# wl_phy_rxt_secure register map
Vendor: Texas Instruments
Peripheral module from a debugger description file (folder CC35X1E).
Registers are 32-bit, access per field, no defined reset value unless marked. A register's access mark holds for its fields unless they carry their own. Offsets are as the file gives them; lines under a group give offsets from that group; [hi:lo] are bit positions; {n}, {i} and the like mark numbered series; 'fields as' and 'values as' point back to an identical list; <NAME> marks a mode.

## wl_phy_rxt_secure (part 1 of 2)
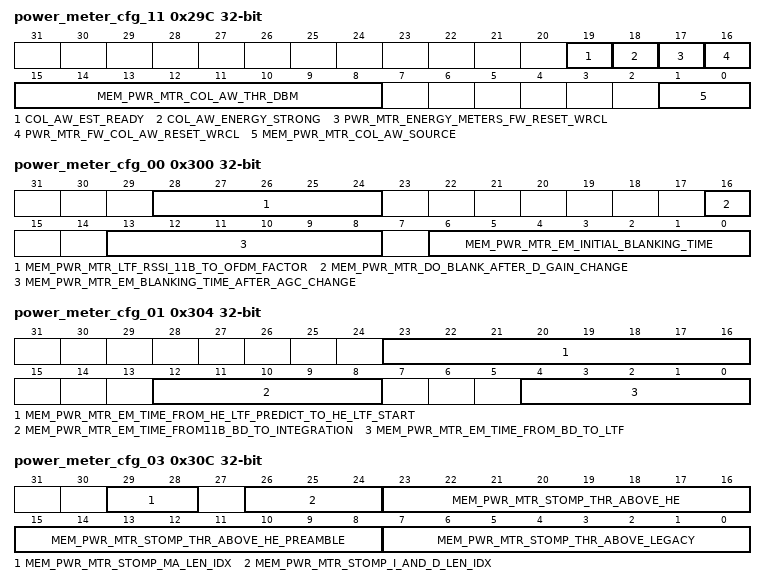
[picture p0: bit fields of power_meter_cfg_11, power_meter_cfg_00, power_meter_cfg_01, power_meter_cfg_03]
0x29C power_meter_cfg_11 — Collision Awareness Detector
  [19] COL_AW_EST_READY ro — Status, indicates that mem_col_aw_energy_strong reading is valid
  [18] COL_AW_ENERGY_STRONG ro — Status, high if module detected 'strong' energy
  [17] PWR_MTR_ENERGY_METERS_FW_RESET_WRCL wo — power estimation fw reset
  [16] PWR_MTR_FW_COL_AW_RESET_WRCL wo — Resets the collision awarenes detector so it can use next estimation
  [15:8] MEM_PWR_MTR_COL_AW_THR_DBM rw — Threshold value for comparisson
  [1:0] MEM_PWR_MTR_COL_AW_SOURCE rw — MUX control for path estimation
0x300 power_meter_cfg_00 — Rx PowerMeter configuration reg
  [28:24] MEM_PWR_MTR_LTF_RSSI_11B_TO_OFDM_FACTOR rw
  [16] MEM_PWR_MTR_DO_BLANK_AFTER_D_GAIN_CHANGE rw — 1 - Any DGain change will result in a 1-clock 'blanking' period, causing the estimation period to be re-synched with the new values. 0 - DGain changes will not cause a blanking period nor re-synching.
  [13:8] MEM_PWR_MTR_EM_BLANKING_TIME_AFTER_AGC_CHANGE rw — Duration MaskFSM stays in state Blanking (i.e. masked), following an AGC step. Not used for Digital-Gain change. [40MHz cycles]
  [6:0] MEM_PWR_MTR_EM_INITIAL_BLANKING_TIME rw — Duration MaskFSM stays in state Idle (i.e. masked), following turn on or RxEn. [40MHz cycles]
0x304 power_meter_cfg_01 — Rx PowerMeter configuration reg
  [23:16] MEM_PWR_MTR_EM_TIME_FROM_HE_LTF_PREDICT_TO_HE_LTF_START rw — Duration RssiLtfFSM stays in state WaitForHeLtfStart following entrance to HeStf. (in other words, time from RxControl FSM start of HeStf state, till HeLtf reaches energy meter)[40MHz cycles]
  [12:8] MEM_PWR_MTR_EM_TIME_FROM11B_BD_TO_INTEGRATION rw — Duration RssiLtfFSM stays in state WaitForLegLtfStart following an 11B 'BD' event. [40MHz cycles]
  [4:0] MEM_PWR_MTR_EM_TIME_FROM_BD_TO_LTF rw — Duration RssiLtfFSM stays in state WaitForLegLtfStart following a BD event from the TdAcq. This accounts for delay as well as propagation. [40MHz cycles]
0x308 power_meter_cfg_02 reset 0x8040 — Rx PowerMeter configuration reg
  [8:0] MEM_PWR_MTR_EM_NORM_FACTOR_DB rw — Norm factor. Should include dBFS to dBm, Trace Loss and gain variation. Formula for dBFS to dBm is 10log10(VFullScale^2/(R*10^-3)) = 10log10(VFullScale^2/(50*10^-3)) which is 13dB in case of FPGA and 7 in silicon. [dB] Default = 7dB * 2^ 3= 56 <6.3s>
0x30C power_meter_cfg_03 — Rx PowerMeter configuration reg
  [29:28] MEM_PWR_MTR_STOMP_MA_LEN_IDX rw — {0} Length is 1 (no MA) {1} Length is 2 {2} Length is 4 {3} Length is 8
  [26:24] MEM_PWR_MTR_STOMP_I_AND_D_LEN_IDX rw — {0} No I and D (input at 40MHz) {1} 100nSec I and D {2} 200nSec I and D {3} 400nSec I and D {4} Use configurable length I and D as input
  [23:16] MEM_PWR_MTR_STOMP_THR_ABOVE_HE rw — Stomp threshold used during HE parts. [dB above RSSI estimation on HE-LTF] default = 14dB*2^2 = 56 <6.2u>
  [15:8] MEM_PWR_MTR_STOMP_THR_ABOVE_HE_PREAMBLE rw — Stomp threshold used during HE-Preamble parts. [dB above RSSI estimation on L-LTF] default = 63.75dB*2^2 = 255 <6.2u>
  [7:0] MEM_PWR_MTR_STOMP_THR_ABOVE_LEGACY rw — Stomp threshold used during non-HE parts. [dB above RSSI estimation on L-LTF] default = 14dB*2^2 = 56 <6.2u>
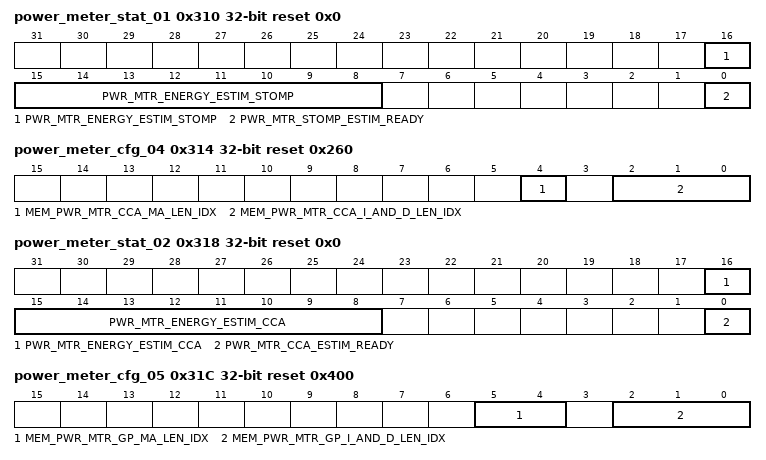
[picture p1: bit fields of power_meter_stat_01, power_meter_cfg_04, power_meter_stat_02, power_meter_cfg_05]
0x310 power_meter_stat_01 ro reset 0x0 — Rx PowerMeter Status reg
  [16:8] PWR_MTR_ENERGY_ESTIM_STOMP — Status Reg with energy estimation by Stomp path. Note that positive values in register indicate negative [dBm] (i.e. multiply with -1 and then shift, and then you get the dBm value) RO - <7.2u>
  [0] PWR_MTR_STOMP_ESTIM_READY — Status reg signifying Stomp energy estimation is valid and not during a mask RO
0x314 power_meter_cfg_04 reset 0x260 (reset mask 0xFFFFFFE0) — Rx PowerMeter configuration reg
  [4] MEM_PWR_MTR_CCA_MA_LEN_IDX rw — {0} Length is 1 (no MA) {1} Length is 2 Note that DGain changes might come at 800nSec intervals, so total CCA integration length should be shorter.
  [2:0] MEM_PWR_MTR_CCA_I_AND_D_LEN_IDX rw — {0} No I and D (input at 40MHz) {1} 100nSec I and D {2} 200nSec I and D {3} 400nSec I and D {4} Use configurable length I and D as input
0x318 power_meter_stat_02 ro reset 0x0 — Rx PowerMeter Status reg
  [16:8] PWR_MTR_ENERGY_ESTIM_CCA — Status Reg with energy estimation by CCA path. Note that positive values in register indicate negative [dBm] (i.e. multiply with -1 and then shift, and then you get the dBm value) RO - <7.2u>
  [0] PWR_MTR_CCA_ESTIM_READY — Status reg signifying CCA energy estimation is valid and not during a mask RO
0x31C power_meter_cfg_05 reset 0x400 (reset mask 0xFFFFFFC0) — Rx PowerMeter configuration reg
  [5:4] MEM_PWR_MTR_GP_MA_LEN_IDX rw — Note: Will only work when EnGpMa register is 1. {0} Length is 1 (no MA) {1} Length is 2 {2} Length is 4 {3} Length is 8
  [2:0] MEM_PWR_MTR_GP_I_AND_D_LEN_IDX rw — {0} No I and D (input at 40MHz) {1} 100nSec I and D {2} 200nSec I and D {3} 400nSec I and D {4} Use configurable length I and D as input
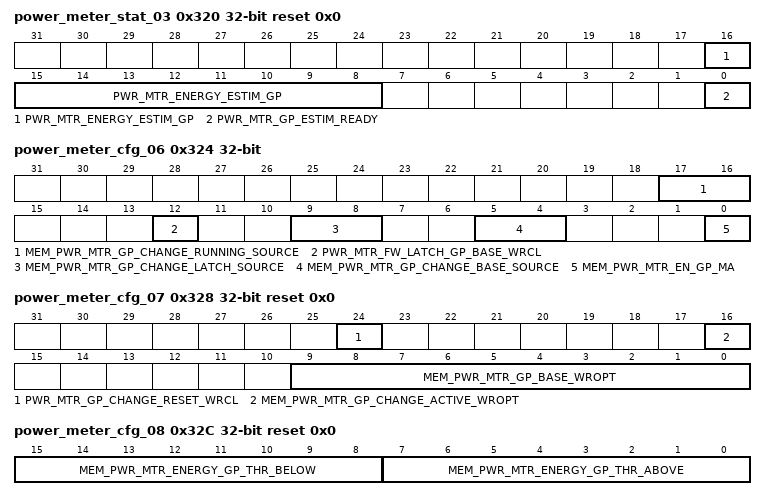
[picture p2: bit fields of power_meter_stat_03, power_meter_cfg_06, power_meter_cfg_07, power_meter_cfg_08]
0x320 power_meter_stat_03 ro reset 0x0 — Rx PowerMeter Status reg
  [16:8] PWR_MTR_ENERGY_ESTIM_GP — Status Reg with energy estimation by GP path. Note that positive values in register indicate negative [dBm] (i.e. multiply with -1 and then shift, and then you get the dBm value) RO - <7.2u>
  [0] PWR_MTR_GP_ESTIM_READY — Status reg signifying GP energy estimation is valid and not during a mask RO
0x324 power_meter_cfg_06 — Rx PowerMeter configuration reg
  [17:16] MEM_PWR_MTR_GP_CHANGE_RUNNING_SOURCE rw — Source of the GP 'Running' energy {0} - LTF RSSI {1} - Stomp MA {2} - CCA MA {3} - GP MA The running-energy chosen here is compared (with margins of EnergyGpThrAbove and EnergyGpThrBelow) with the 'baseline' energy chosen by GpChangeBaseSource (and latched by GpChangeLatchSource), to generate the GpEnergyHigh and GpEnergyLow IRQ's
  [12] PWR_MTR_FW_LATCH_GP_BASE_WRCL wo — (Self-Clear) When GpChangeLatchSource is set to {3}, a pulse in this register will latch the baseline energy and allow the GP energy change detector to start working. If the baseline energy is to be set by FW (and not latched from one of the energy estimations), GpChangeLatchSource should be set to {3}, baseline energy should be written into GpBase by FW, and a pulse here should NOT be initiated.
  [9:8] MEM_PWR_MTR_GP_CHANGE_LATCH_SOURCE rw
  [5:4] MEM_PWR_MTR_GP_CHANGE_BASE_SOURCE rw — Source of the GP 'baseline' energy. {0} - LTF RSSI {1} - Stomp MA {2} - CCA MA {3} - GP MA Note that the latching of the source into the 'baseline' depends on the GpChangeLatchSource register
  [0] MEM_PWR_MTR_EN_GP_MA rw — Saves power consumption when 0
0x328 power_meter_cfg_07 reset 0x0 — Rx PowerMeter configuration reg
  [24] PWR_MTR_GP_CHANGE_RESET_WRCL wo — Resets the GpChangeActive register to 0. This resetting should be done before the expected latching of the baseline. (Self-Clear)
  [16] MEM_PWR_MTR_GP_CHANGE_ACTIVE_WROPT rw — Marks that a latching of the GP-Baseline has taken place, and so the GP-energy-change detector readings are valid. This register is reset to 0 by the GpChangeReset register, and set to 1 automatically when the baseline latching occurs. Note that this register is also 'Write-Opt'. In case GP-Baseline is set by FW (and not latched automatically nor manually), FW may write this register to mark to any relevant entity that GP-Baseline is valid and that GP IRQs are up and running. Write-Opt
  [9:0] MEM_PWR_MTR_GP_BASE_WROPT rw — The GP baseline energy. ?????<8.5s>???? (Write-Opt) The source of this register may be an energy reading from the GpChangeBaseSource, or it may be written by FW. In case it is written by FW, the GpChangeLatchSource register should be set to {3}, and the FwLatchGpBase should be kept at 0. In case this register's source is not FW, the value in this reg is valid only after baseline is 'latched'. This is marked in the 'GpChangeActive' register.
0x32C power_meter_cfg_08 reset 0x0 — Rx PowerMeter configuration reg
  [15:8] MEM_PWR_MTR_ENERGY_GP_THR_BELOW rw — Any 'GP-Running' energy which is lower than GpBase by more than the value set in this register, will cause a 'GpEnergyLow' IRQ. Note that this is valid only after GpBase is valid (written in FW or latched as shown in GpChangeActive). [dB] Default 6gB --> 24 (<6.2>)
  [7:0] MEM_PWR_MTR_ENERGY_GP_THR_ABOVE rw — Any 'GP-Running' energy which is higher than GpBase by more than the value set in this register, will cause a 'GpEnergyHigh' IRQ. Note that this is valid only after GpBase is valid (written in FW or latched as shown in GpChangeActive). [dB] Default 6gB --> 24 (<6.2>)
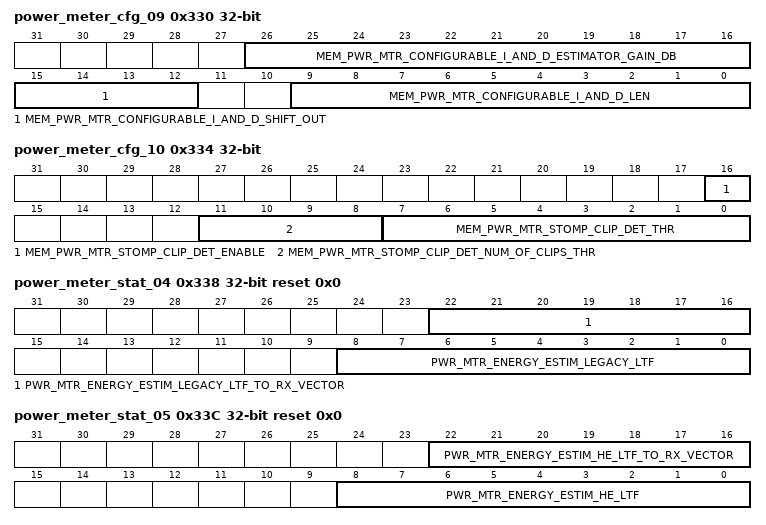
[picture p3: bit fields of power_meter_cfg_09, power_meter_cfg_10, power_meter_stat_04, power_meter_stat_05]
0x330 power_meter_cfg_09 — Rx PowerMeter configuration reg
  [26:16] MEM_PWR_MTR_CONFIGURABLE_I_AND_D_ESTIMATOR_GAIN_DB rw — The gain compensation of the configurable IandD, in [dB]. (based on its length, which is ConfigurableIandDLen, and on the number of output shifts, which is ConfigurableIandDShiftOut). The value from this register will be added to the estimated energy when using configurable I and D length. Default: 1.03125 (*2^32 )--> 33 (<6.5>)
  [15:12] MEM_PWR_MTR_CONFIGURABLE_I_AND_D_SHIFT_OUT rw — Number of right-shifts at configurable I and D module output. In general for integration length of 4 put 2, for integration length of 8 put 3, for integration length of 16 put 4, and so on. Supported range: (0,10) (<4.0>)
  [9:0] MEM_PWR_MTR_CONFIGURABLE_I_AND_D_LEN rw — Configurable I and D integration length. Used only when GpIandDLenIdx, CcaIandDLenIdx or StompIandDLenIdx are configured to {4} [40MHz clock cycles] <10.0u>
0x334 power_meter_cfg_10 — Rx PowerMeter configuration reg
  [16] MEM_PWR_MTR_STOMP_CLIP_DET_ENABLE rw, [11:8] MEM_PWR_MTR_STOMP_CLIP_DET_NUM_OF_CLIPS_THR rw, [7:0] MEM_PWR_MTR_STOMP_CLIP_DET_THR rw
0x338 power_meter_stat_04 ro reset 0x0 — Rx PowerMeter Status reg
  [22:16] PWR_MTR_ENERGY_ESTIM_LEGACY_LTF_TO_RX_VECTOR — Same as EnergyEstimLegacyLtf, but in format matching RxVector, i.e. 0=-110dBm, 127=17dBm RO - <7.0u>
  [8:0] PWR_MTR_ENERGY_ESTIM_LEGACY_LTF — Energy estimation of Legacy-LTF part. In 11B estimation is also performed. Locked automatically. Note that positive values in register indicate negative [dBm] (i.e. multiply with -1 and then shift, and then you get the dBm value) [-dBm]
0x33C power_meter_stat_05 ro reset 0x0 — Rx PowerMeter Status reg
  [22:16] PWR_MTR_ENERGY_ESTIM_HE_LTF_TO_RX_VECTOR — Same as EnergyEstimHeLtf, but in format matching RxVector, i.e. 0=-110dBm, 127=17dBm RO - <7.0u>
  [8:0] PWR_MTR_ENERGY_ESTIM_HE_LTF — Energy estimation of HE-LTF part. Locked automatically. Note that positive values in register indicate negative [dBm] (i.e. multiply with -1 and then shift, and then you get the dBm value) [-dBm] RO - <7.2u>
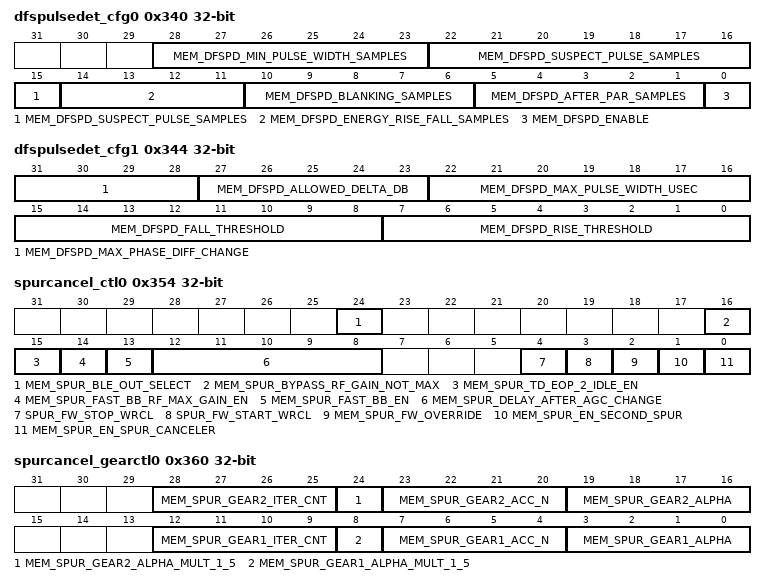
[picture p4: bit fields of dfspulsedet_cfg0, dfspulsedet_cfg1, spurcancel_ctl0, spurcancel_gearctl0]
0x340 dfspulsedet_cfg0 — DFSPulseDetector Configuration Register0
  [28:23] MEM_DFSPD_MIN_PULSE_WIDTH_SAMPLES rw — Format <6.0u>: Min pulse width in samples (40MHz)
  [22:15] MEM_DFSPD_SUSPECT_PULSE_SAMPLES rw — Format <8.0u>: Number of samples of low energy demanded after pulse s end
  [14:11] MEM_DFSPD_ENERGY_RISE_FALL_SAMPLES rw — Format <4.0u>: Number of samples in waiting states (see SM) after energy rise/fall
  [10:6] MEM_DFSPD_BLANKING_SAMPLES rw — Format <5.0u>: Number of samples waiting in BLANKING state
  [5:1] MEM_DFSPD_AFTER_PAR_SAMPLES rw — Format <5.0u>: Number of low samples needed to leave PAR state
  [0] MEM_DFSPD_ENABLE rw — DFS Pulse Detector Enable
0x344 dfspulsedet_cfg1 rw — DFSPulseDetector Configuration Register1
  [31:28] MEM_DFSPD_MAX_PHASE_DIFF_CHANGE — Format <0.4u>: Phase Diff threshold for chirp identification.
  [27:23] MEM_DFSPD_ALLOWED_DELTA_DB — Format <3.1u>: Allowed energy delta in dB. Used for stabilization identification.
  [22:16] MEM_DFSPD_MAX_PULSE_WIDTH_USEC — Format <7.0u>: Max pulse width in usec.
  [15:8] MEM_DFSPD_FALL_THRESHOLD — Format <6.0u>: Energy rise threshold in dB.
  [7:0] MEM_DFSPD_RISE_THRESHOLD — Format <6.0u>: Energy rise threshold in dB.
0x354 spurcancel_ctl0 — Spur Canceler Control Register 0
  [24] MEM_SPUR_BLE_OUT_SELECT rw
  [16] MEM_SPUR_BYPASS_RF_GAIN_NOT_MAX rw — If set, the spur canceler will be bypassed when RF gain is not at max value
  [15] MEM_SPUR_TD_EOP_2_IDLE_EN rw — If enabled, EOP packet pulse resets the SC correction into idle.
  [14] MEM_SPUR_FAST_BB_RF_MAX_GAIN_EN rw — If set, BB(VGA) change will cause scaling of the SC correction value (according to the VGA change) without reset of the SC module only when RF is in max gain (LNA+TA).
  [13] MEM_SPUR_FAST_BB_EN rw — If set, BB(VGA) change will cause scaling of the SC correction value (according to the VGA change) without reset of the SC module (spur is assumed constant during BB change).
  [12:8] MEM_SPUR_DELAY_AFTER_AGC_CHANGE rw — Format <5.0u>: Delay value after agc change (RfChange|BBChange) - Blanking. The delay is in 40 MHZ Samples
  [4] SPUR_FW_STOP_WRCL wo — Stop the SC correction - triggered from FW. Self Clear
  [3] SPUR_FW_START_WRCL wo — Start new SC correction - triggered from FW. Self Clear
  [2] MEM_SPUR_FW_OVERRIDE rw — If set, only the FW controls start/stop and not inner signals such as Abort/EOP/StartTd
  [1] MEM_SPUR_EN_SECOND_SPUR rw — Enabling the second spur removal
  [0] MEM_SPUR_EN_SPUR_CANCELER rw — Enable to the sequencer SM. If reset, the spur canceler is bypassed and the SM is disabled
0x358 spurcancel_freq1 reset 0x0 — Spur 1 Frequency Control Register
  [20:0] MEM_SPUR_FREQ1_DIV_FS rw — Format <0.21s>: The BB frequency of the first spur in units of DRX frequency (40MHz)
0x35C spurcancel_freq2 reset 0x0 — Spur 2 Frequency Control Register
  [20:0] MEM_SPUR_FREQ2_DIV_FS rw — Format <0.21s>: The BB frequency of the second spur in units of DRX frequency (40MHz)
0x360 spurcancel_gearctl0 — Spur Gear Control Register 0
  [28:25] MEM_SPUR_GEAR2_ITER_CNT rw — Format <4.0u>: Number of clocks to stay at Gear1. value is 2^(int)
  [24] MEM_SPUR_GEAR2_ALPHA_MULT_1_5 rw — 1.5 multiplier enable for Alfa of Gear 2
  [23:20] MEM_SPUR_GEAR2_ACC_N rw — Format <4.0u>: Accumulator duration (40Mhz cycles) for Gear2. Value is 2^(int). The value should be lower than Gear1IterCnt to produce at least a single correction in Gear2
  [19:16] MEM_SPUR_GEAR2_ALPHA rw — Format <4.0u>: Alfa value for Gear2. Value is (For example, value of 4 corresponds to 1/16).
  [12:9] MEM_SPUR_GEAR1_ITER_CNT rw — Format <4.0u>: Number of clocks to stay at Gear1. value is 2^(int)
  [8] MEM_SPUR_GEAR1_ALPHA_MULT_1_5 rw — 1.5 multiplier enable for Alfa of Gear 1
  [7:4] MEM_SPUR_GEAR1_ACC_N rw — Format <4.0u>: Accumulator duration (40Mhz cycles) for Gear1. Value is 2^(int). The value should be lower than Gear1IterCnt to produce at least a single correction in Gear1
  [3:0] MEM_SPUR_GEAR1_ALPHA rw — Format <4.0u>: Alfa value for Gear1. Value is (For example, value of 4 corresponds to 1/16).
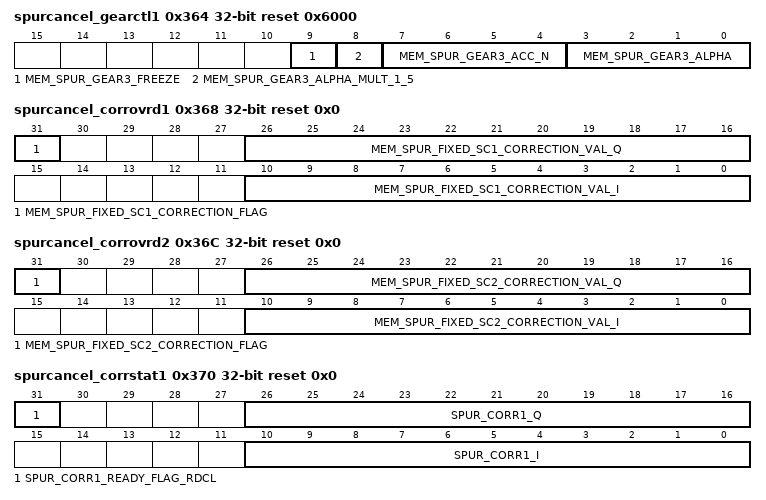
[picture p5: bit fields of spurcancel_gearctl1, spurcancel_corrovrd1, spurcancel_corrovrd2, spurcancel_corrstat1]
0x364 spurcancel_gearctl1 reset 0x6000 (reset mask 0xFFFFFC00) — Spur Gear Control Register 1
  [9] MEM_SPUR_GEAR3_FREEZE rw — Freeze adaptation for gear3
  [8] MEM_SPUR_GEAR3_ALPHA_MULT_1_5 rw — 1.5 multiplier enable for Alfa of Gear 3
  [7:4] MEM_SPUR_GEAR3_ACC_N rw — Format <4.0u>: Accumulator duration (40Mhz cycles) for Gear3. Value is 2^(int).
  [3:0] MEM_SPUR_GEAR3_ALPHA rw — Format <4.0u>: Alfa value for Gear3. Value is (For example, value of 4 corresponds to 1/16).
0x368 spurcancel_corrovrd1 reset 0x0 — Spur 1 Correction Override Register
  [31] MEM_SPUR_FIXED_SC1_CORRECTION_FLAG rw — If set, overwrite spur1 correction by FixedSc1CorrectionVal_XX
  [26:16] MEM_SPUR_FIXED_SC1_CORRECTION_VAL_Q rw — Format <0.11s>: Imaginary part of external forced spur1 correction
  [10:0] MEM_SPUR_FIXED_SC1_CORRECTION_VAL_I rw — Format <0.11s>: Real part of external forced spur1 correction
0x36C spurcancel_corrovrd2 reset 0x0 — Spur 2 Correction Override Register
  [31] MEM_SPUR_FIXED_SC2_CORRECTION_FLAG rw — If set, overwrite spur2 correction by FixedSc2CorrectionVal_XX
  [26:16] MEM_SPUR_FIXED_SC2_CORRECTION_VAL_Q rw — Format <0.11s>: Imaginary part of external forced spur2 correction
  [10:0] MEM_SPUR_FIXED_SC2_CORRECTION_VAL_I rw — Format <0.11s>: Real part of external forced spur2 correction
0x370 spurcancel_corrstat1 ro reset 0x0 — Spur 1 Correction Status Register
  [31] SPUR_CORR1_READY_FLAG_RDCL — Set to high every update of Corr value.
  [26:16] SPUR_CORR1_Q — Format <0.11s>: Spur correction value to be applied on the first DC cancellation sub-module. This value corresponds to the 1st Spur level.
  [10:0] SPUR_CORR1_I — Format <0.11s>: Spur correction value to be applied on the first DC cancellation sub-module. This value corresponds to the 1st Spur level.
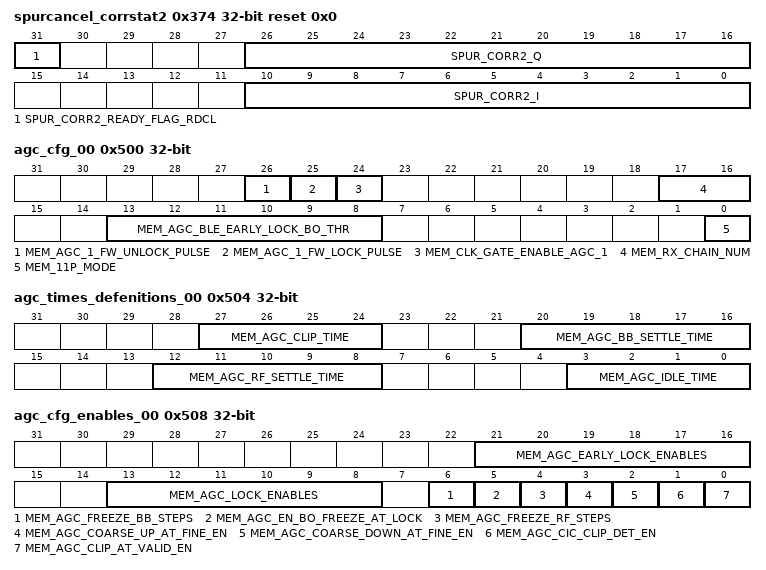
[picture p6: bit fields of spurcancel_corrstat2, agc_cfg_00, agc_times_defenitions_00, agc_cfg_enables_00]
0x374 spurcancel_corrstat2 ro reset 0x0 — Spur 2 Correction Status Register
  [31] SPUR_CORR2_READY_FLAG_RDCL — Set to high every update of Corr value.
  [26:16] SPUR_CORR2_Q — Format <0.11s>: Spur correction value to be applied on the first DC cancellation sub-module. This value corresponds to the 2nd Spur level.
  [10:0] SPUR_CORR2_I — Format <0.11s>: Spur correction value to be applied on the first DC cancellation sub-module. This value corresponds to the 2nd Spur level.
0x500 agc_cfg_00
  [26] MEM_AGC_1_FW_UNLOCK_PULSE rw, [25] MEM_AGC_1_FW_LOCK_PULSE rw, [24] MEM_CLK_GATE_ENABLE_AGC_1 rw, [17:16] MEM_RX_CHAIN_NUM rw, [13:8] MEM_AGC_BLE_EARLY_LOCK_BO_THR rw, [0] MEM_11P_MODE rw
0x504 agc_times_defenitions_00
  [27:24] MEM_AGC_CLIP_TIME rw — Settling time for clip event.
  [20:16] MEM_AGC_BB_SETTLE_TIME rw — Time for VGA will settle after gain step.Field value is number of samples
  [12:8] MEM_AGC_RF_SETTLE_TIME rw — Time for LNA/TA will settle after gain step. Field value is number of samples
  [3:0] MEM_AGC_IDLE_TIME rw
0x508 agc_cfg_enables_00
  [21:16] MEM_AGC_EARLY_LOCK_ENABLES rw — OneHotEarly LockPolicy: BD, BD_11b, PD, PD+delay, PD_11b, AGC 1st step+delay. 0-dont lock 1-lock at the first event
  [13:8] MEM_AGC_LOCK_ENABLES rw
  [6] MEM_AGC_FREEZE_BB_STEPS rw — When asserted BB steps are not allowed
  [5] MEM_AGC_EN_BO_FREEZE_AT_LOCK rw — BD, BD_11b, PD, PD+delay, PD_11b, AGC 1st step+delay.
  [4] MEM_AGC_FREEZE_RF_STEPS rw — When asserted RF steps are not allowed
  [3] MEM_AGC_COARSE_UP_AT_FINE_EN rw — When false, disabled the CompCoarseHigh at Fine state
  [2] MEM_AGC_COARSE_DOWN_AT_FINE_EN rw — When false, disabled the CompCoarseLow at Fine state
  [1] MEM_AGC_CIC_CLIP_DET_EN rw — Enable bit for clip detector
  [0] MEM_AGC_CLIP_AT_VALID_EN rw — Bit enable for consider clipping at power valid state
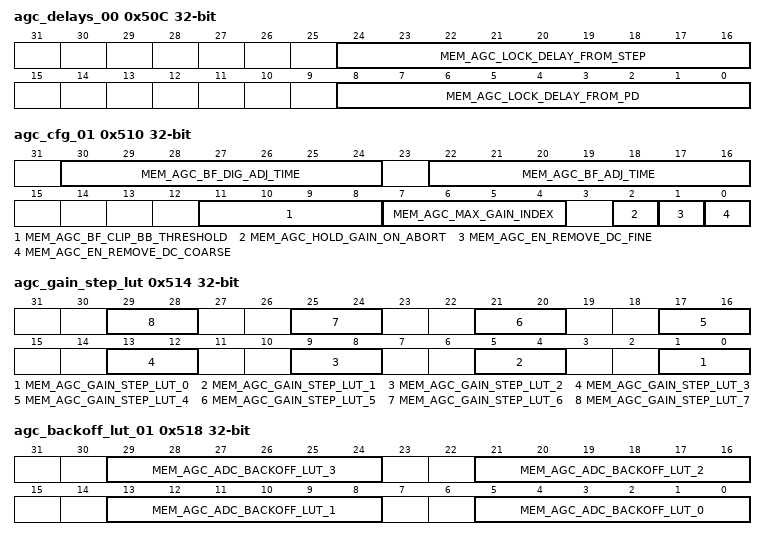
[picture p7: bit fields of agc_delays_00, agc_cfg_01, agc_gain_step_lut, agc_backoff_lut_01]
0x50C agc_delays_00
  [24:16] MEM_AGC_LOCK_DELAY_FROM_STEP rw — Delay from PD used for Mask lock policy policy (Used both for early Lock or Lock)
  [8:0] MEM_AGC_LOCK_DELAY_FROM_PD rw — Delay from AGC 1st step used for Mask lock policy (Used both for early Lock or Lock)
0x510 agc_cfg_01
  [30:24] MEM_AGC_BF_DIG_ADJ_TIME rw
  [22:16] MEM_AGC_BF_ADJ_TIME rw — Re adjustment time of the AGC in the HE-STF
  [11:8] MEM_AGC_BF_CLIP_BB_THRESHOLD rw
  [7:4] MEM_AGC_MAX_GAIN_INDEX rw — 1 lock at the first event
  [2] MEM_AGC_HOLD_GAIN_ON_ABORT rw — 0 dont lock
  [1] MEM_AGC_EN_REMOVE_DC_FINE rw — Bit Enable decide if remove DC from fine power estimation
  [0] MEM_AGC_EN_REMOVE_DC_COARSE rw — Bit Enable decide if remove DC from coarse power estimation
0x514 agc_gain_step_lut
  [4n+1:4n] MEM_AGC_GAIN_STEP_LUT_{n} rw (n=0..7) — Step size for each RF index (just for low)
0x518 agc_backoff_lut_01
  [8n+5:8n] MEM_AGC_ADC_BACKOFF_LUT_{n} rw (n=0..3) — Analog Backoff for each Rf index [dB] <5.1u>
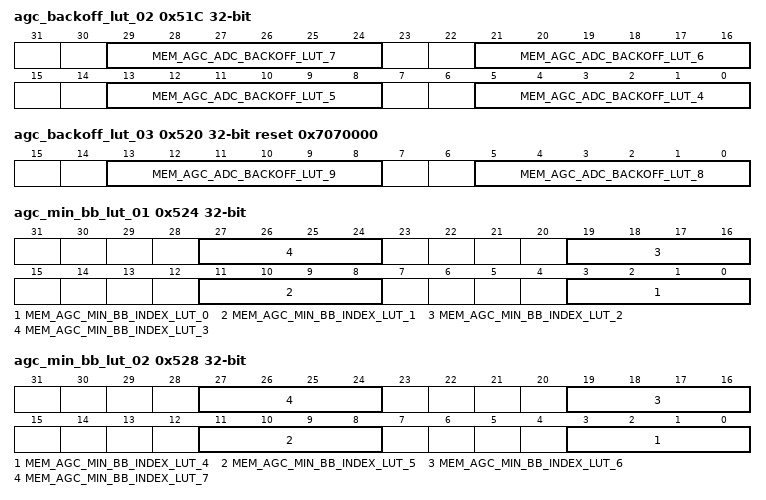
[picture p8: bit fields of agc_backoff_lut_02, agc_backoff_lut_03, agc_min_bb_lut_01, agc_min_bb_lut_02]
0x51C agc_backoff_lut_02
  [8n-27:8n-32] MEM_AGC_ADC_BACKOFF_LUT_{n} rw (n=4..7) — Analog Backoff for each Rf index [dB] <5.1u>
0x520 agc_backoff_lut_03 reset 0x7070000 (reset mask 0xFFFFC000)
  [13:8] MEM_AGC_ADC_BACKOFF_LUT_9 rw — Analog Backoff for each Rf index [dB] <5.1u>
  [5:0] MEM_AGC_ADC_BACKOFF_LUT_8 rw — Analog Backoff for each Rf index [dB] <5.1u>
0x524 agc_min_bb_lut_01
  [8n+3:8n] MEM_AGC_MIN_BB_INDEX_LUT_{n} rw (n=0..3)
0x528 agc_min_bb_lut_02
  [8n-29:8n-32] MEM_AGC_MIN_BB_INDEX_LUT_{n} rw (n=4..7)
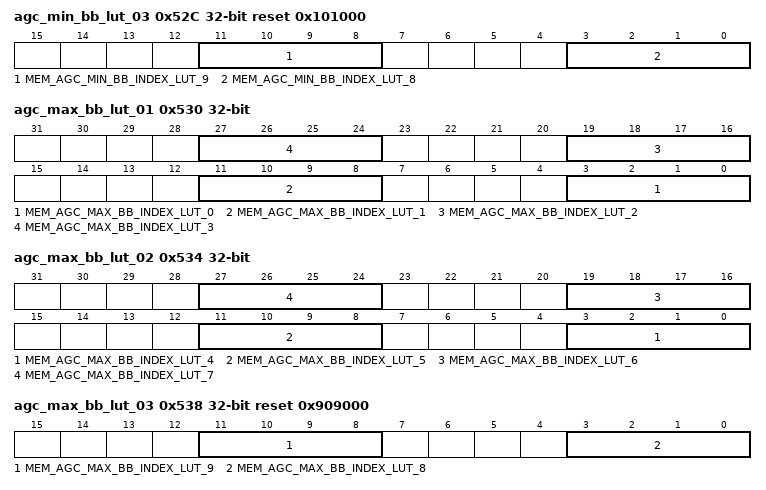
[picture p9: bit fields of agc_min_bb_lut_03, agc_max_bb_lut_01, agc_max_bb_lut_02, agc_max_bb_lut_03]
0x52C agc_min_bb_lut_03 reset 0x101000 (reset mask 0xFFFFF000)
  [11:8] MEM_AGC_MIN_BB_INDEX_LUT_9 rw, [3:0] MEM_AGC_MIN_BB_INDEX_LUT_8 rw
0x530 agc_max_bb_lut_01
  [8n+3:8n] MEM_AGC_MAX_BB_INDEX_LUT_{n} rw (n=0..3)
0x534 agc_max_bb_lut_02
  [8n-29:8n-32] MEM_AGC_MAX_BB_INDEX_LUT_{n} rw (n=4..7)
0x538 agc_max_bb_lut_03 reset 0x909000 (reset mask 0xFFFFF000)
  [11:8] MEM_AGC_MAX_BB_INDEX_LUT_9 rw, [3:0] MEM_AGC_MAX_BB_INDEX_LUT_8 rw
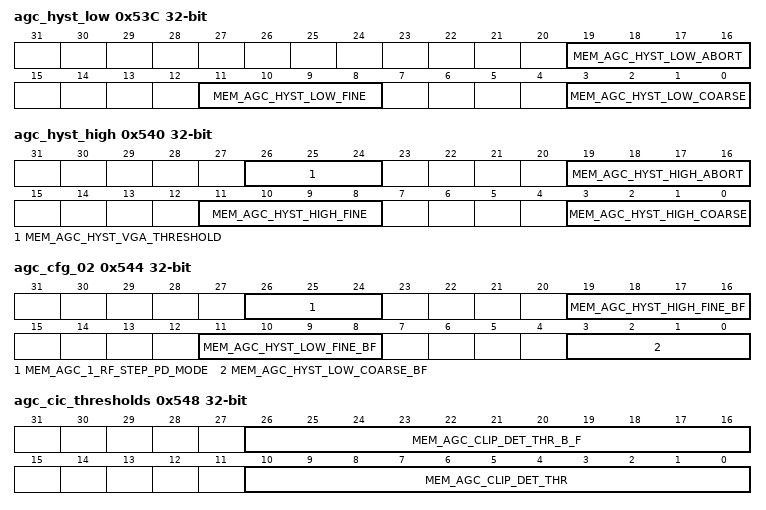
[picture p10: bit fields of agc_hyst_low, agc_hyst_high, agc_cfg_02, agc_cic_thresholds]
0x53C agc_hyst_low
  [19:16] MEM_AGC_HYST_LOW_ABORT rw — Threshold for abort delta Gain to decrease gain [dB] <4.0u>
  [11:8] MEM_AGC_HYST_LOW_FINE rw — Threshold for fine delta Gain to decrease gain [dB] <4.0>
  [3:0] MEM_AGC_HYST_LOW_COARSE rw — Threshold for coarse delta Gain to decrease gain [dB] <4.0>
0x540 agc_hyst_high
  [26:24] MEM_AGC_HYST_VGA_THRESHOLD rw — Threshold for BB to assert
  [19:16] MEM_AGC_HYST_HIGH_ABORT rw — Threshold for Abort delta Gain to increase gain [dB] <4.0u>
  [11:8] MEM_AGC_HYST_HIGH_FINE rw — Threshold for fine delta Gain to increase gain [dB] <4.0u>
  [3:0] MEM_AGC_HYST_HIGH_COARSE rw — Threshold for coarse delta Gain to increase gain [dB] <4.0>
0x544 agc_cfg_02
  [26:24] MEM_AGC_1_RF_STEP_PD_MODE rw
  [19:16] MEM_AGC_HYST_HIGH_FINE_BF rw — Threshold for fine delta Gain to increase gain [dB], in Beam Form (11he) adjustment <4.0>
  [11:8] MEM_AGC_HYST_LOW_FINE_BF rw — Threshold for fine delta Gain to decrease gain [dB], in Beam Form (11he) adjustment <4.0u>
  [3:0] MEM_AGC_HYST_LOW_COARSE_BF rw — Threshold for coarse delta Gain to decrease gain [dB], in Beam Form (11he) adjustment
0x548 agc_cic_thresholds
  [26:16] MEM_AGC_CLIP_DET_THR_B_F rw — Threshold for CIC Clip detector in BF re-adjustment, 0.8545: <0.11u>
  [10:0] MEM_AGC_CLIP_DET_THR rw — Threshold for CIC Clip detector, 0.8545: <0.11u>
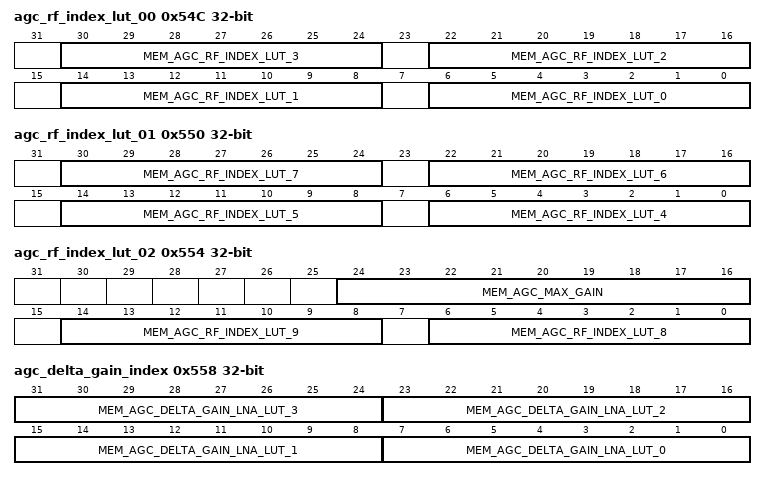
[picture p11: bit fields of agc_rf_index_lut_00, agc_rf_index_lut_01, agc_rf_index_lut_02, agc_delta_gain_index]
0x54C agc_rf_index_lut_00
  [8n+6:8n] MEM_AGC_RF_INDEX_LUT_{n} rw (n=0..3)
0x550 agc_rf_index_lut_01
  [8n-26:8n-32] MEM_AGC_RF_INDEX_LUT_{n} rw (n=4..7)
0x554 agc_rf_index_lut_02
  [24:16] MEM_AGC_MAX_GAIN rw, [14:8] MEM_AGC_RF_INDEX_LUT_9 rw, [6:0] MEM_AGC_RF_INDEX_LUT_8 rw
0x558 agc_delta_gain_index rw
  [8n+7:8n] MEM_AGC_DELTA_GAIN_LNA_LUT_{n} (n=0..3)
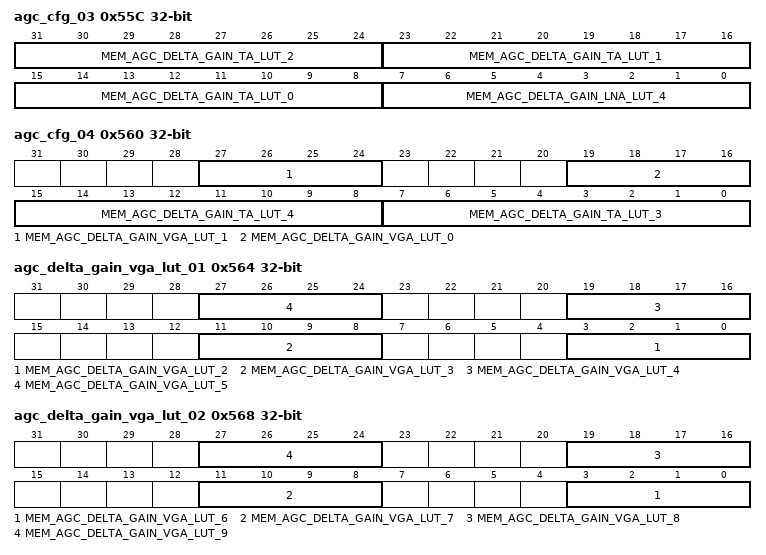
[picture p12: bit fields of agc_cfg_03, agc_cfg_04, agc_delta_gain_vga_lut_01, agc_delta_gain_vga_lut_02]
0x55C agc_cfg_03 rw
  [31:24] MEM_AGC_DELTA_GAIN_TA_LUT_2, [23:16] MEM_AGC_DELTA_GAIN_TA_LUT_1, [15:8] MEM_AGC_DELTA_GAIN_TA_LUT_0, [7:0] MEM_AGC_DELTA_GAIN_LNA_LUT_4
0x560 agc_cfg_04
  [27:24] MEM_AGC_DELTA_GAIN_VGA_LUT_1 rw, [19:16] MEM_AGC_DELTA_GAIN_VGA_LUT_0 rw, [15:8] MEM_AGC_DELTA_GAIN_TA_LUT_4 rw, [7:0] MEM_AGC_DELTA_GAIN_TA_LUT_3 rw
0x564 agc_delta_gain_vga_lut_01
  [8n-13:8n-16] MEM_AGC_DELTA_GAIN_VGA_LUT_{n} rw (n=2..5)
0x568 agc_delta_gain_vga_lut_02
  [8n-45:8n-48] MEM_AGC_DELTA_GAIN_VGA_LUT_{n} rw (n=6..9)
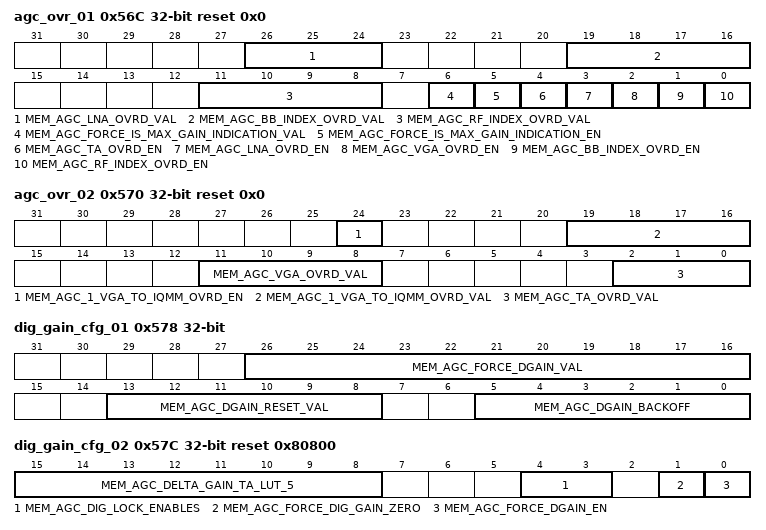
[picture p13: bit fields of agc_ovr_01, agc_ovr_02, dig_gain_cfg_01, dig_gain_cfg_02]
0x56C agc_ovr_01 reset 0x0
  [26:24] MEM_AGC_LNA_OVRD_VAL rw
  [19:16] MEM_AGC_BB_INDEX_OVRD_VAL rw
  [11:8] MEM_AGC_RF_INDEX_OVRD_VAL rw
  [6] MEM_AGC_FORCE_IS_MAX_GAIN_INDICATION_VAL rw — For Debug, when forcing AGC gain index
  [5] MEM_AGC_FORCE_IS_MAX_GAIN_INDICATION_EN rw — For Debug, when forcing AGC gain index
  [4] MEM_AGC_TA_OVRD_EN rw
  [3] MEM_AGC_LNA_OVRD_EN rw
  [2] MEM_AGC_VGA_OVRD_EN rw
  [1] MEM_AGC_BB_INDEX_OVRD_EN rw
  [0] MEM_AGC_RF_INDEX_OVRD_EN rw
0x570 agc_ovr_02 reset 0x0
  [24] MEM_AGC_1_VGA_TO_IQMM_OVRD_EN rw, [19:16] MEM_AGC_1_VGA_TO_IQMM_OVRD_VAL rw, [11:8] MEM_AGC_VGA_OVRD_VAL rw, [2:0] MEM_AGC_TA_OVRD_VAL rw
0x574 dig_gain_cfg_00 reset 0x28A — Time parameteres
  [5:0] MEM_AGC_DGAIN_GROUP_DELAY rw — Delay between Resampler and Spur Canceler [samples]
0x578 dig_gain_cfg_01 — Gain values
  [26:16] MEM_AGC_FORCE_DGAIN_VAL rw — Force Digital gain control word
  [13:8] MEM_AGC_DGAIN_RESET_VAL rw — Initial value for digital gain [dB]
  [5:0] MEM_AGC_DGAIN_BACKOFF rw — Digital Backoff after Spur Canceler [dB]
0x57C dig_gain_cfg_02 reset 0x80800 (reset mask 0xFFFFFF00) — Settings
  [15:8] MEM_AGC_DELTA_GAIN_TA_LUT_5 rw
  [4:3] MEM_AGC_DIG_LOCK_ENABLES rw — 00: not locked 01: one shot after analog change 10: lock at BD 11: lock at min (one shot after analog change, BD)
  [1] MEM_AGC_FORCE_DIG_GAIN_ZERO rw — Froce the digital gain to zero dB gain when not in analog max gain
  [0] MEM_AGC_FORCE_DGAIN_EN rw — Force Digital gain control word enable
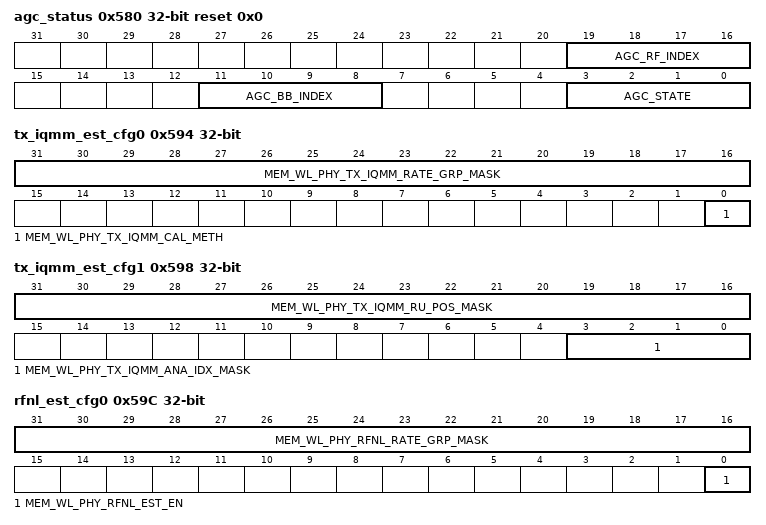
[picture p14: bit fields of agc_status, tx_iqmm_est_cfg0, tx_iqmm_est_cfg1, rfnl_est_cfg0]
0x580 agc_status ro reset 0x0
  [19:16] AGC_RF_INDEX, [11:8] AGC_BB_INDEX, [3:0] AGC_STATE
0x584 total_gain_status ro reset 0x0
  [11:0] TOTAL_GAIN_STAT — Total Gain <8.4>
0x590 tx_cal_en reset 0x0
  [0] MEM_WL_PHY_TX_CAL_EN rw — '0'- Disable the block '1'- Enable the block
0x594 tx_iqmm_est_cfg0
  [31:16] MEM_WL_PHY_TX_IQMM_RATE_GRP_MASK rw — Enables TX IQMM estimator only on packets of rate-groups (binary decoded) that are set high in this field
  [0] MEM_WL_PHY_TX_IQMM_CAL_METH rw — Old method - 0; New method - 1; New Tx IQMM method requires 2 iterations of Timing estimation. If TX_IQMM_CAL_METHOD_FLAG=1 -> Duplicate stages 7,8 of sequencer SM.
0x598 tx_iqmm_est_cfg1
  [31:16] MEM_WL_PHY_TX_IQMM_RU_POS_MASK rw — Enables TX IQMM estimator only on packets of RU positions (binary decoded) that are set high in this field
  [3:0] MEM_WL_PHY_TX_IQMM_ANA_IDX_MASK rw — Enables TX IQMM estimator only on packets of analog setting that is set high in this field
0x59C rfnl_est_cfg0
  [31:16] MEM_WL_PHY_RFNL_RATE_GRP_MASK rw — Enables TX RFNL estimator only on packets of rate-groups (binary decoded) that are set high in this field
  [0] MEM_WL_PHY_RFNL_EST_EN rw — '1'- Enables RFNL estimation on upcoming packet(s)
0x600 rfnl_est_cfg1
  [31:16] MEM_WL_PHY_RFNL_RU_POS_MASK rw — Enables TX RFNL estimator only on packets of RU positions (binary decoded) that are set high in this field
  [3:0] MEM_WL_PHY_RFNL_ANA_IDX_MASK rw — Enables TX RFNL estimator only on packets of analog setting that is set in this field
0x610 rfnl_bo_cfg
  [31:24] MEM_WL_PHY_RFNL_DURATION_LOW rw — Minimal duration of the packet required to be processed in RFNL estimator in units of 4usec
  [18] MEM_WL_PHY_RFNL_TRAP_BYPASS rw — '0'- Use packet trap (which rate etc...to work on) '1'- Disregard trap altogether
  [17] MEM_WL_PHY_RFNL_BO_TRAP_ALL_PKTS rw — '0'- will operate RFNL BO trap only on 11ax trigger based packets '1'- will operate BO trap on all packets
  [16] MEM_WL_PHY_RFNL_BO_TRAP_BYPASS rw — '0'- Apply RFNL BO trap when packet is 11ax trigger-based. '1'- Disregard BO trap (i.e. work on any back-off)
  [13:8] MEM_WL_PHY_RFNL_TRIG_BO_LO rw — RFNL estimation low threshold on packet's desired output BO that the TxCfg block targeted (when packet is a triggered 11ax)
  [5:0] MEM_WL_PHY_RFNL_TRIG_BO_HI rw — RFNL estimation high threshold on packet's desired output BO that the TxCfg block targeted (when packet is a triggered 11ax)
0x614 tx_iqmm_bo_cfg
  [31:24] MEM_WL_PHY_TX_IQMM_DURATION_LOW rw — Minimal duration of the packet required to be processed in TX IQMM estimator in units of 4usec
  [18] MEM_WL_PHY_TX_IQMM_TRAP_BYPASS rw — '0'- Use packet trap (which rate etc...to work on) '1'- Disregard trap altogether
  [17] MEM_WL_PHY_TX_IQMM_BO_TRAP_ALL_PKTS rw — '0'- will operate TX IQMM BO trap only on 11ax trigger based packets. '1'- will operate BO trap on all packets
  [16] MEM_WL_PHY_TX_IQMM_BO_TRAP_BYPASS rw — '0'- Apply IQMM BO trap when packet is 11ax trigger-based. '1' - Disregard BO trap (i.e. work on any back-off)
  [13:8] MEM_WL_PHY_TX_IQMM_TRIG_BO_LO rw — IQMM estimation low threshold on packet's desired output BO that the TxCfg block targeted (when packet is a triggered 11ax
  [5:0] MEM_WL_PHY_TX_IQMM_TRIG_BO_HI rw — IQMM estimation high threshold on packet's desired output BO that the TxCfg block targeted (when packet is a triggered 11ax)
0x618 tx_cal_cfg
  [19:16] MEM_WL_PHY_WAIT_FOR_TX rw — Delay in units of cycles, with an offset of 1 cycle (0x0 represents 1 cycle of delay, 0x1 is 2 cycles of delay etc). Otherwise 0x0 would have been an invalid value. Delays the start logic until input from TxConfig module arrives at Start_Logic inputs.
  [8] MEM_WL_PHY_START_SRC rw — 0x0 - Start signal is TxCgfOBOReady 0x1 - Start signal is START_FW register field content.
  [0] WL_PHY_START_FW_WRCL wo — Start signal when START_SOURCE is set to 0x1
0x61C tx_iqmm_delay
  [23:16] MEM_WL_PHY_TX_IQMM_STOP rw — A delay from packet beginning (in 3.2us granularity) after which the IQMM estimator processing of samples stops (if packet stops before that then processing also stops). Value has to be higher than value of TX_IQMM_EST_START_TIME.
  [7:0] MEM_WL_PHY_TX_IQMM_START rw — A delay from packet beginning (in 3.2us granularity) after which the IQMM estimator processing of samples starts. Value has to be lower than value of TX_IQMM_EST_STOP_TIME.
0x620 rfnl_delay
  [23:16] MEM_WL_PHY_RFNL_STOP rw — A delay from packet beginning (in 3.2us granularity) after which the RFNL estimator processing of samples stops (if packet stops before that then processing also stops). Value has to be higher than value of RFNL_EST_START_TIME.
  [7:0] MEM_WL_PHY_RFNL_START rw — A delay from packet beginning (in 3.2us granularity) after which the RFNL estimator processing of samples starts. Value has to be lower than value of RFNL_EST_STOP_TIME.
0x624 tx_cal_seq_cfg
  [25:16] MEM_WL_PHY_SEQ_WAIT_FOR_FFT_INP rw — Amount of clocks the sequencer is dwelling on WaitForFftInput state.
  [9:0] MEM_WL_PHY_SEQ_WAIT_FOR_LTF_CAP rw — Amount of clocks the sequencer is dwelling on WaitForLTFCapture state.
0x628 tx_cal_delay_stat ro reset 0x20402040
  [22:16] WL_PHY_LATCHED_FRAC_DELAY — Latches the output FracDelayToResampler signal when ResamplerFracDelayAlign goes high.
  [6:0] WL_PHY_LATCHED_INT_DELAY — Latches the internal IntDelay signal (integer delay) from Timing Manipulation module to the memory when ResamplerFracDelayAlign goes high.
0x62C tx_cal_resample_cfg0
  [31:24] MEM_WL_PHY_TIMING_INT_OVR_VAL rw — See TIMING_INT_OVR_EN
  [16] MEM_WL_PHY_TIMING_INT_OVR_EN rw — When set high the value in TIMING_INT_OVR_VAL overrides the (TimingEstIntIn + TimingIntOffset) result
  [14:8] MEM_WL_PHY_TIMING_INT_OFFSET rw — Offset that is added to the integer delay estimation
  [0] MEM_WL_PHY_TIMING_INVERT rw — When set high, the timing offset estimation result is inverted (before any further manipulations are performed)
0x630 tx_cal_resample_cfg1
  [30:24] MEM_WL_PHY_TIMING_FRAC_OVR_VAL rw — See TIMING_FRAC_OVR_EN
  [16] MEM_WL_PHY_TIMING_FRAC_OVR_EN rw — When set high the value in TIMING_FRAC_OVR_VAL overrides the (TimingEstIntIn + TimingIntOffset) result
  [14:8] MEM_WL_PHY_TIMING_FRAC_OFFSET rw — Offset that is added to the overall TimingOffsetIn
  [0] MEM_WL_PHY_TIMING_FRAC_INVERT rw — When set high, the fractional delay towards the resampler is inverted
0x634 tx_cal_resample_stat ro reset 0x0
  [21:16] WL_PHY_TIMING_EST_FRAC — Read out of fractional part of the timing offset estimation
  [5:0] WL_PHY_TIMING_EST_INT — Read out of integer part of the timing offset estimation
0x638 tx_cal_ovr_ctrl reset 0x0
  [17] MEM_WL_PHY_TX_IQMM_EST_EN_VAL rw — Override value for result of EstEnable logic of the Tx Calibration Manager (IqmmEstEn)
  [16] MEM_WL_PHY_TX_IQMM_EST_EN_OVR rw — Override enable for result of EstEnable logic of the Tx Calibration Manager (IqmmEstEn)
  [1] MEM_WL_PHY_RFNL_EST_EN_VAL rw — Override value for result of EstEnable logic of the Tx Calibration Manager (RfnlEstEn)
  [0] MEM_WL_PHY_RFNL_EST_EN_OVR rw — Override enable for result of EstEnable logic of the Tx Calibration Manager (RfnlEstEn)
0x63C tx_cal_phase_rslt_stat ro reset 0x0
  [23:16] WL_PHY_COMMON_PHASE_RSLT_ASYM — Result of 2nd iteration from Timing Estimation block.
  [7:0] WL_PHY_COMMON_PHASE_RSLT_SYM — Result of 1st iteration from Timing Estimation block.
0x640 tx_cal_stat ro reset 0x0
  [1] WL_PHY_TXCAL_STAT_IQMM_EST_PERF_RDCL — Indication that an IQMM estimation was triggered since last time this flag was read
  [0] WL_PHY_TXCAL_STAT_RFNL_EST_PERF_RDCL — Indication that an RFNL estimation was triggered since last time this flag was read
0x644 tx_cal_ofdm_bin_cfg0
  [30:16] MEM_WL_PHY_REF_BSEL_P_MASK_ASYM rw — Combination of positive bins from LTF so bins X[-k]=-X[k] are chosen for common phase estimation in the Timing Estimation module.
  [14:0] MEM_WL_PHY_REF_BSEL_P_MASK_SYM rw — Combination of positive bins from LTF so bins X[-k]=X[k] are chosen for common phase estimation in the Timing Estimation module.
0x648 tx_cal_ofdm_bin_cfg1
  [30:16] MEM_WL_PHY_REF_BSEL_N_MASK_ASYM rw — Combination of negative bins from LTF so bins X[-k]=-X[k] are chosen for common phase estimation in the Timing Estimation module.
  [14:0] MEM_WL_PHY_REF_BSEL_N_MASK_SYM rw — Combination of negative bins from LTF so bins X[-k]=X[k] are chosen for common phase estimation in the Timing Estimation module.
0x64C tx_iqmm_est_ctrl0 reset 0x0
  [0] MEM_TXIQMMEST_COUNTER_RESET_PULSE wo — Functional reset
0x654 tx_iqmm_est_mag_cfg reset 0x3206000 (reset mask 0xFFFFE000) — MAG_CFG: Magnitude threshold limits
  [12:8] MEM_TXIQMMEST_TX_IQMM_EST_HIGH_MAG rw — High magnitude threshold. Samples with RefMagnitude values up to this threshold will be processed. Note that this threshold should be set according to the amount of buckets to be used in RFNL estimator
  [4:0] MEM_TXIQMMEST_TX_IQMM_EST_LOW_MAG rw — Low magnitude threshold. Samples with RefMagnitude values down to this threshold will be processed. Note that this threshold should be set according to the amount of buckets to be used in RFNL estimator
0x658 tx_iqmm_est_smpl_cfg reset 0xF3CF3C — SMPL_CFG: Maximum sample count.
  [11:0] MEM_TXIQMMEST_TX_IQMM_CNT_HIGH_TH rw — When the amount of samples processed reached this value the calibration stops (must be set to values below 3900 to avoid risk of overflow).
0x65C tx_iqmm_est_smpl_stat ro reset 0x0 — SMPL_STAT: Actual sample count.
  [11:0] TXIQMMEST_SAMPLES_PROCESSED — The counter value that indicates the amount of samples processed
0x660 tx_iqmm_est_xryr_accum reset 0x0 — XRYR_ACCUM: Accumulated product after N number of samples. (SMPL_STAT)
  [20:0] TXIQMMEST_XRYR_ACCUM_WROPT rw — Cross-correlation term XrYr
0x664 tx_iqmm_est_xiyi_accum reset 0x0 — XIYI_ACCUM: Accumulated product after N number of samples. (SMPL_STAT)
  [20:0] TXIQMMEST_XIYI_ACCUM_WROPT rw — Cross-correlation term XiYi
0x668 tx_iqmm_est_xryi_accum reset 0x0 — XRYI_ACCUM: Accumulated product after N number of samples. (SMPL_STAT)
  [20:0] TXIQMMEST_XRYI_ACCUM_WROPT rw — Cross-correlation term XrYi
0x66C tx_iqmm_est_xiyr_accum reset 0x0 — XIYR_ACCUM: Accumulated product after N number of samples. (SMPL_STAT)
  [20:0] TXIQMMEST_XIYR_ACCUM_WROPT rw — Cross-correlation term XiYr
0x670 tx_iqmm_est_xrxr_accum reset 0x0 — XRXR_ACCUM: Accumulated product after N number of samples. (SMPL_STAT)
  [20:0] TXIQMMEST_XRXR_ACCUM_WROPT rw — RefSig term Xr2
0x674 tx_iqmm_est_xixi_accum reset 0x0 — XIXI_ACCUM: Accumulated product after N number of samples. (SMPL_STAT)
  [20:0] TXIQMMEST_XIXI_ACCUM_WROPT rw — RefSig term Xi2
0x678 tx_iqmm_est_xrxi_accum reset 0x0 — XRXI_ACCUM: Accumulated product after N number of samples. (SMPL_STAT)
  [20:0] TXIQMMEST_XRXI_ACCUM_WROPT rw — RefSig term XrXi
0x67C tx_rfnl_cfg_00
  [24:16] MEM_RFNL_DIG_GAIN_FINE rw, [14:8] MEM_RFNL_REF_GAIN rw, [7:6] MEM_RFNL_DIG_GAIN_COARSE rw, [0] MEM_DIG_GAIN_SEL rw
0x680 tx_rfnl_cfg_01 reset 0x0
  [18:16] MEM_RFNL_DONE_CRIT rw, [8] RFNL_WIPE_RESULTS_WRCL wo, [5] RFNL_NL_ACCUM_CLIPPED_RDCL ro, [4] RFNL_NL_IMAG_CLIPPED_RDCL ro, [3] RFNL_NL_REAL_CLIPPED_RDCL ro, [2] RFNL_REF_BO_ROUND_RDCL ro, [1] RFNL_REF_BO_CLIPPED_RDCL ro, [0] RFNL_REF_CLIPPED_RDCL ro
0x684 tx_rfnl_cfg_02 reset 0x0
  [26:16] MEM_RFNL_LOW_CNT_TH rw, [10:0] MEM_RFNL_HIGH_CNT_TH rw
0x688 tx_rfnl_cfg_03 rw reset 0x0
  [31:0] MEM_RFNL_LOW_CNT_BUCKET_MASK
0x68C tx_rfnl_cfg_04 ro reset 0x0
  [10:0] RFNL_HIGH_CNT_RO
0x690 tx_rfnl_cfg_05 ro reset 0x0
  [31:0] RFNL_LOW_CNT_RO
0x700 dfs_pattern_detector_status_register_1 ro reset 0x0
  [26:24] CHIRP_WR_PTR, [18:16] CHIRP_RD_PTR, [11:8] PULSE_WR_PTR, [3:0] PULSE_RD_PTR
0x704 dfs_pattern_detector_status_register_2 reset 0x0
  [8] IRQ_STATUS ro, [1] DFS_PULSE_BUFFER_RESET_WRCL wo, [0] DFS_CHIRP_BUFFER_RESET_WRCL wo
0x708 dfs_pattern_detector_cfg_0 rw
  [31:24] MEM_DFS_CHIRP_MAX_WIDTH — Chirp maximum width (us)
  [23:16] MEM_DFS_CHIRP_MIN_WIDTH — Chirp minimum width (us)
  [15:8] MEM_DFS_SHORT_MAX_WIDTH — Short pulses maximum width (us)
  [7:0] MEM_DFS_SHORT_MIN_WIDTH — Short pulses minimum width (us)
0x70C dfs_pattern_detector_cfg_1
  [28] MEM_DFS_BUFFERS_LOCK rw — Do not write Buffer
  [27:24] MEM_DFS_PULSE_THRESHOLD rw — Used for short pulses when number of pulses in buffer reach this number call PHY CTX by IRQ
  [16:0] MEM_DFS_PULSE_LIFETIME rw — Lifetime of a pulse in the buffer. If this time passed, reset the buffer and write the new pulse as first one.#br#
0x710 dfs_pattern_detector_cfg_2
  [26:24] MEM_DFS_CHIRP_THRESHOLD rw — Used for short pulses when number of pulses in buffer reach this number call PHY CTX by IRQ
  [23:0] MEM_DFS_CHIRP_LIFETIME rw — Lifetime of a pulse in the buffer. If this time passed, reset the buffer and write the new pulse as first one.#br#
0x714 tx_calib_cfg_0 reset 0x0
  [31:24] MEM_C_3 rw, [23:16] MEM_C_2 rw, [15:8] MEM_C_1 rw, [6:0] MEM_C_0 rw
0x718 tx_calib_cfg_1 reset 0x0
  [10] MEM_WL_PHY_TX_IQMM_EST_EN rw, [9] MEM_WL_PHY_SEQ_FW_RELEASE_STATE_9 rw, [8] MEM_WL_PHY_SEQ_FW_HOLD_STATE_9 rw, [6:0] MEM_C_4 rw
0x71C rx_interfacr_control reset 0x4000000 (reset mask 0xFFFC0000)
  [17] MEM_RX_INTERFACE_N_Q rw, [16] MEM_RX_INTERFACE_N_I rw, [9:8] MEM_RX_INTERFACE_SQ rw, [1:0] MEM_RX_INTERFACE_SI rw
0x720 rx_trng_status ro reset 0xF
  [1:0] RX_TRNG_STATUS
0x724 rx_aux_cfg reset 0x0
  [8] START_TD_AUX_WRCL wo, [0] MEM_USE_AUX_CONFIG rw
0x800 tx_rfnl_cfg_06 rw reset 0x0
  [31:0] MEM_RFNL_FW_READ_DATA_8FC_WRMEMP
0x900 dfs_pattern_detector_pulse_buffer rw reset 0x0 — DFS Pulse Buffer register
  [31:0] MEM_DFS_PULSE_REPORT_RAM_93C_WRMEM
0xA00 dfs_pattern_detector_chirp_buffer rw reset 0x0 — DFS Chirp Buffer register
  [31:0] MEM_DFS_CHIRP_REPORT_RAM_A1C_WRMEM
0xC00 tx_cal_ram_read rw reset 0x0
  [31:0] MEM_TX_CAL_RAM_DFC_WRMEMP
0xE00 rx_iqmm_ram rw reset 0x0
  [31:0] MEM_RX_IQMM_RAM_E3C_WRMEMP
